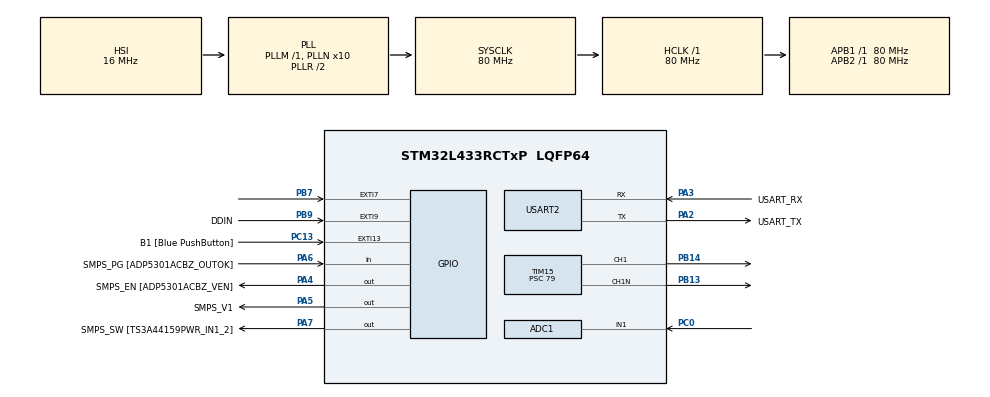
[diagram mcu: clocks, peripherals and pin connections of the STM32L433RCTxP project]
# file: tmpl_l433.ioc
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ADC1.Channel-2\#ChannelRegularConversion=ADC_CHANNEL_VREFINT
ADC1.NbrOfConversionFlag=1
ADC1.OffsetNumber-2\#ChannelRegularConversion=ADC_OFFSET_NONE
ADC1.Rank-2\#ChannelRegularConversion=1
ADC1.SamplingTime-2\#ChannelRegularConversion=ADC_SAMPLETIME_2CYCLES_5
ADC1.master=1
Mcu.Family=STM32L4
Mcu.Name=STM32L433RCTxP
Mcu.Package=LQFP64
NVIC.EXTI9_5_IRQn=true\:0\:0\:false\:false\:true\:true\:true\:true
NVIC.PriorityGroup=NVIC_PRIORITYGROUP_4
NVIC.TIM2_IRQn=true\:0\:0\:false\:false\:true\:true\:true\:true
PA13\ (JTMS-SWDIO).GPIO_Label=TMS
PA13\ (JTMS-SWDIO).Mode=Serial_Wire
PA13\ (JTMS-SWDIO).Signal=SYS_JTMS-SWDIO
PA14\ (JTCK-SWCLK).GPIO_Label=TCK
PA14\ (JTCK-SWCLK).Mode=Serial_Wire
PA14\ (JTCK-SWCLK).Signal=SYS_JTCK-SWCLK
PA2.GPIO_Label=USART_TX
PA2.GPIO_Mode=GPIO_MODE_AF_PP
PA2.GPIO_PuPd=GPIO_NOPULL
PA2.GPIO_Speed=GPIO_SPEED_FREQ_VERY_HIGH
PA2.Mode=Asynchronous
PA2.Signal=USART2_TX
PA3.GPIO_Label=USART_RX
PA3.GPIO_Mode=GPIO_MODE_AF_PP
PA3.GPIO_PuPd=GPIO_NOPULL
PA3.GPIO_Speed=GPIO_SPEED_FREQ_VERY_HIGH
PA3.Mode=Asynchronous
PA3.Signal=USART2_RX
PA4.GPIO_Label=SMPS_EN [ADP5301ACBZ_VEN]
PA4.Signal=GPIO_Output
PA5.GPIO_Label=SMPS_V1
PA5.GPIO_ModeDefaultOutputPP=GPIO_MODE_OUTPUT_PP
PA5.GPIO_PuPd=GPIO_NOPULL
PA5.GPIO_Speed=GPIO_SPEED_FREQ_LOW
PA5.Signal=GPIO_Output
PA6.GPIO_Label=SMPS_PG [ADP5301ACBZ_OUTOK]
PA6.GPIO_PuPd=GPIO_PULLUP
PA6.Signal=GPIO_Input
PA7.GPIO_Label=SMPS_SW [TS3A44159PWR_IN1_2]
PA7.Signal=GPIO_Output
PB13.Mode=PWM Generation1 CH1 CH1N
PB13.Signal=TIM15_CH1N
PB14.Signal=S_TIM15_CH1
PB3\ (JTDO-TRACESWO).GPIO_Label=SWO
PB3\ (JTDO-TRACESWO).Signal=SYS_JTDO-SWO
PB7.GPIO_ModeDefaultEXTI=GPIO_MODE_IT_FALLING
PB7.GPIO_PuPd=GPIO_PULLUP
PB7.Signal=GPXTI7
PB9.GPIO_Label=DDIN
PB9.Signal=GPXTI9
PC0.Signal=ADCx_IN1
PC13.GPIO_Label=B1 [Blue PushButton]
PC13.GPIO_ModeDefaultEXTI=GPIO_MODE_IT_FALLING
PC13.GPIO_PuPd=GPIO_NOPULL
PC13.Signal=GPXTI13
PC14-OSC32_IN\ (PC14).Mode=LSE-External-Oscillator
PC14-OSC32_IN\ (PC14).Signal=RCC_OSC32_IN
PC15-OSC32_OUT\ (PC15).Mode=LSE-External-Oscillator
PC15-OSC32_OUT\ (PC15).Signal=RCC_OSC32_OUT
PH0-OSC_IN\ (PH0).GPIO_Label=MCO
PH0-OSC_IN\ (PH0).Mode=HSE-External-Clock-Source
PH0-OSC_IN\ (PH0).Signal=RCC_OSC_IN
PH1-OSC_OUT\ (PH1).Signal=RCC_OSC_OUT
ProjectManager.HeapSize=0x200
ProjectManager.StackSize=0x400
ProjectManager.TargetToolchain=STM32CubeIDE
RCC.ADCFreq_Value=64000000
RCC.AHBFreq_Value=80000000
RCC.APB1Freq_Value=80000000
RCC.APB1TimFreq_Value=80000000
RCC.APB2Freq_Value=80000000
RCC.APB2TimFreq_Value=80000000
RCC.CortexFreq_Value=80000000
RCC.HCLKFreq_Value=80000000
RCC.HSE_VALUE=8000000
RCC.HSI48_VALUE=48000000
RCC.HSI_VALUE=16000000
RCC.MSI_VALUE=4000000
RCC.PLLN=10
RCC.PLLSourceVirtual=RCC_PLLSOURCE_HSI
RCC.PREFETCH_ENABLE=1
RCC.SYSCLKFreq_VALUE=80000000
RCC.SYSCLKSource=RCC_SYSCLKSOURCE_PLLCLK
RCC.USBFreq_Value=64000000
RCC.VCOOutputFreq_Value=160000000
SH.ADCx_IN1.0=ADC1_IN1,IN1-Single-Ended
SH.S_TIM15_CH1.0=TIM15_CH1,PWM Generation1 CH1 CH1N
TIM15.Channel-PWM\ Generation1\ CH1\ CH1N=TIM_CHANNEL_1
TIM15.Period=5000
TIM15.Prescaler=79
TIM2.Period=8000
USART2.VirtualMode-Asynchronous=VM_ASYNC
VP_ADC1_Vref_Input.Mode=IN-Vrefint
VP_TIM15_VS_ClockSourceINT.Mode=Internal
VP_TIM2_VS_ClockSourceINT.Mode=Internal
board=NUCLEO-L433RC-P

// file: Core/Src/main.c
/* USER CODE BEGIN Header */
/**
  ******************************************************************************
  * @file           : main.c
  * @brief          : Main program body
  ******************************************************************************
  * @attention
  *
  * <h2><center>&copy; Copyright (c) 2022 STMicroelectronics.
  * All rights reserved.</center></h2>
  *
  * This software component is licensed by ST under BSD 3-Clause license,
  * the "License"; You may not use this file except in compliance with the
  * License. You may obtain a copy of the License at:
  *                        opensource.org/licenses/BSD-3-Clause
  *
  ******************************************************************************
  */
/* USER CODE END Header */
#include "main.h"
#include "adc.h"
#include "tim.h"
#include "usart.h"
#include "gpio.h"

void SystemClock_Config(void);

int main(void)
{

  /* MCU Configuration--------------------------------------------------------*/

  /* Reset of all peripherals, Initializes the Flash interface and the Systick. */
  HAL_Init();

  /* Configure the system clock */
  SystemClock_Config();

  /* Initialize all configured peripherals */
  MX_GPIO_Init();
  MX_USART2_UART_Init();
  MX_TIM15_Init();
  MX_TIM2_Init();
  MX_ADC1_Init();
  /* USER CODE BEGIN 2 */
  HAL_TIM_PWM_Start(&htim15, TIM_CHANNEL_1);
  /* USER CODE END 2 */

  /* Infinite loop */
  /* USER CODE BEGIN WHILE */
  extern void app_init();
  app_init();
  while (1)
  {
      extern void app_loop();
      app_loop();
    /* USER CODE END WHILE */

  }
}

void SystemClock_Config(void)
{
  RCC_OscInitTypeDef RCC_OscInitStruct = {0};
  RCC_ClkInitTypeDef RCC_ClkInitStruct = {0};

  /** Configure the main internal regulator output voltage
  */
  if (HAL_PWREx_ControlVoltageScaling(PWR_REGULATOR_VOLTAGE_SCALE1) != HAL_OK)
  {
    Error_Handler();
  }

  /** Initializes the RCC Oscillators according to the specified parameters
  * in the RCC_OscInitTypeDef structure.
  */
  RCC_OscInitStruct.OscillatorType = RCC_OSCILLATORTYPE_HSI;
  RCC_OscInitStruct.HSIState = RCC_HSI_ON;
  RCC_OscInitStruct.HSICalibrationValue = RCC_HSICALIBRATION_DEFAULT;
  RCC_OscInitStruct.PLL.PLLState = RCC_PLL_ON;
  RCC_OscInitStruct.PLL.PLLSource = RCC_PLLSOURCE_HSI;
  RCC_OscInitStruct.PLL.PLLM = 1;
  RCC_OscInitStruct.PLL.PLLN = 10;
  RCC_OscInitStruct.PLL.PLLP = RCC_PLLP_DIV7;
  RCC_OscInitStruct.PLL.PLLQ = RCC_PLLQ_DIV2;
  RCC_OscInitStruct.PLL.PLLR = RCC_PLLR_DIV2;
  if (HAL_RCC_OscConfig(&RCC_OscInitStruct) != HAL_OK)
  {
    Error_Handler();
  }

  /** Initializes the CPU, AHB and APB buses clocks
  */
  RCC_ClkInitStruct.ClockType = RCC_CLOCKTYPE_HCLK|RCC_CLOCKTYPE_SYSCLK
                              |RCC_CLOCKTYPE_PCLK1|RCC_CLOCKTYPE_PCLK2;
  RCC_ClkInitStruct.SYSCLKSource = RCC_SYSCLKSOURCE_PLLCLK;
  RCC_ClkInitStruct.AHBCLKDivider = RCC_SYSCLK_DIV1;
  RCC_ClkInitStruct.APB1CLKDivider = RCC_HCLK_DIV1;
  RCC_ClkInitStruct.APB2CLKDivider = RCC_HCLK_DIV1;

  if (HAL_RCC_ClockConfig(&RCC_ClkInitStruct, FLASH_LATENCY_4) != HAL_OK)
  {
    Error_Handler();
  }
}

void Error_Handler(void)
{
  __disable_irq();
  while (1)
  {
  }
}
